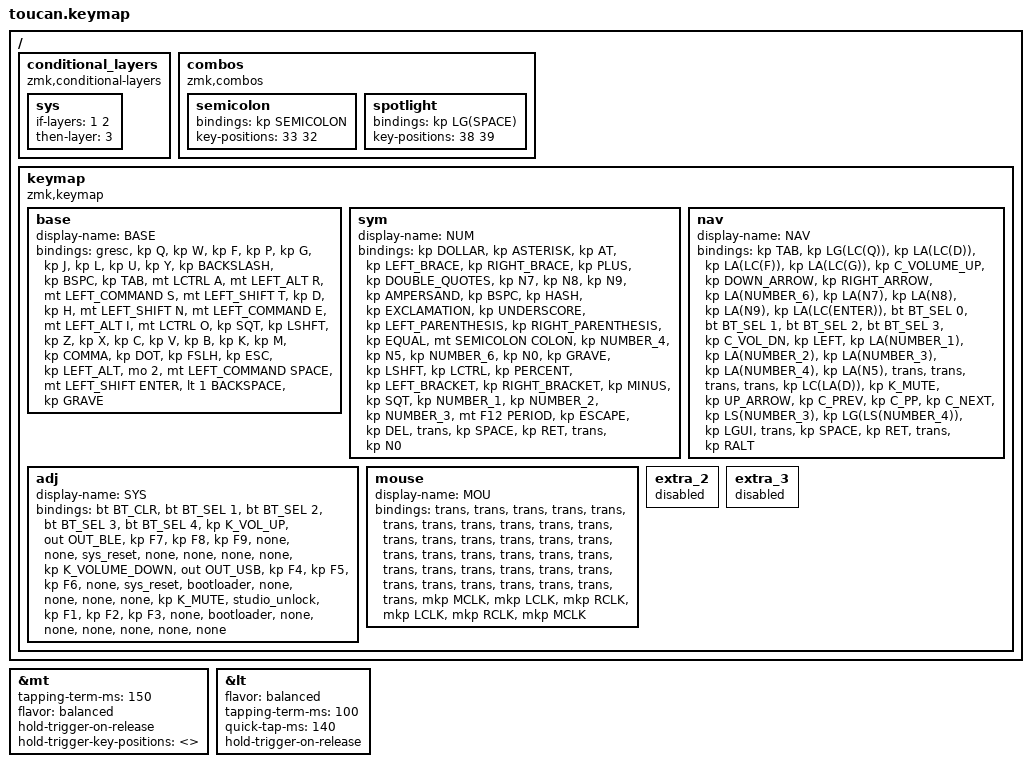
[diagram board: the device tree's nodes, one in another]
#include <behaviors.dtsi>
#include <dt-bindings/zmk/bt.h>
#include <dt-bindings/zmk/keys.h>
#include <dt-bindings/zmk/outputs.h>
#include <dt-bindings/zmk/pointing.h>

#define BASE 0
#define NAV  1
#define SYM  2
#define ADJ  3

&mt {
    tapping-term-ms = <150>;
    flavor = "balanced";
    hold-trigger-on-release;
    hold-trigger-key-positions = <>;
};

&lt {
    flavor = "balanced";
    tapping-term-ms = <100>;
    quick-tap-ms = <140>;
    hold-trigger-on-release;
};

/ {
    conditional_layers {
        compatible = "zmk,conditional-layers";

        sys {
            if-layers = <1 2>;
            then-layer = <3>;
        };
    };

    combos {
        compatible = "zmk,combos";

        semicolon {
            bindings = <&kp SEMICOLON>;
            key-positions = <33 32>;
        };

        spotlight {
            bindings = <&kp LG(SPACE)>;
            key-positions = <38 39>;
        };
    };

    keymap {
        compatible = "zmk,keymap";

        base {
            display-name = "BASE";
            bindings = <
&gresc  &kp Q  &kp W  &kp F  &kp P  &kp G  &kp J  &kp L  &kp U  &kp Y  &kp BACKSLASH  &kp BSPC  &kp TAB  &mt LCTRL A  &mt LEFT_ALT R  &mt LEFT_COMMAND S  &mt LEFT_SHIFT T  &kp D  &kp H  &mt LEFT_SHIFT N  &mt LEFT_COMMAND E  &mt LEFT_ALT I  &mt LCTRL O  &kp SQT  &kp LSHFT  &kp Z  &kp X  &kp C  &kp V  &kp B  &kp K  &kp M  &kp COMMA  &kp DOT  &kp FSLH  &kp ESC  &kp LEFT_ALT  &mo 2  &mt LEFT_COMMAND SPACE  &mt LEFT_SHIFT ENTER  &lt 1 BACKSPACE  &kp GRAVE
            >;
        };

        sym {
            display-name = "NUM";
            bindings = <
&kp DOLLAR  &kp ASTERISK  &kp AT  &kp LEFT_BRACE  &kp RIGHT_BRACE  &kp PLUS  &kp DOUBLE_QUOTES  &kp N7  &kp N8  &kp N9  &kp AMPERSAND  &kp BSPC  &kp HASH  &kp EXCLAMATION  &kp UNDERSCORE  &kp LEFT_PARENTHESIS  &kp RIGHT_PARENTHESIS  &kp EQUAL  &mt SEMICOLON COLON  &kp NUMBER_4  &kp N5  &kp NUMBER_6  &kp N0  &kp GRAVE  &kp LSHFT  &kp LCTRL  &kp PERCENT  &kp LEFT_BRACKET  &kp RIGHT_BRACKET  &kp MINUS  &kp SQT  &kp NUMBER_1  &kp NUMBER_2  &kp NUMBER_3  &mt F12 PERIOD  &kp ESCAPE  &kp DEL  &trans  &kp SPACE  &kp RET  &trans  &kp N0
            >;
        };

        nav {
            display-name = "NAV";
            bindings = <
&kp TAB  &kp LG(LC(Q))  &kp LA(LC(D))  &kp LA(LC(F))  &kp LA(LC(G))  &kp C_VOLUME_UP  &kp DOWN_ARROW  &kp RIGHT_ARROW  &kp LA(NUMBER_6)  &kp LA(N7)  &kp LA(N8)  &kp LA(N9)  &kp LA(LC(ENTER))  &bt BT_SEL 0  &bt BT_SEL 1  &bt BT_SEL 2  &bt BT_SEL 3  &kp C_VOL_DN  &kp LEFT  &kp LA(NUMBER_1)  &kp LA(NUMBER_2)  &kp LA(NUMBER_3)  &kp LA(NUMBER_4)  &kp LA(N5)  &trans  &trans  &trans  &trans  &kp LC(LA(D))  &kp K_MUTE  &kp UP_ARROW  &kp C_PREV  &kp C_PP  &kp C_NEXT  &kp LS(NUMBER_3)  &kp LG(LS(NUMBER_4))  &kp LGUI  &trans  &kp SPACE  &kp RET  &trans  &kp RALT
            >;
        };

        adj {
            display-name = "SYS";
            bindings = <
&bt BT_CLR  &bt BT_SEL 1  &bt BT_SEL 2  &bt BT_SEL 3  &bt BT_SEL 4  &kp K_VOL_UP  &out OUT_BLE  &kp F7  &kp F8  &kp F9  &none  &none  &sys_reset  &none  &none  &none  &none  &kp K_VOLUME_DOWN  &out OUT_USB  &kp F4  &kp F5  &kp F6  &none  &sys_reset  &bootloader  &none  &none  &none  &none  &kp K_MUTE  &studio_unlock  &kp F1  &kp F2  &kp F3  &none  &bootloader  &none  &none  &none  &none  &none  &none
            >;
        };

        mouse {
            display-name = "MOU";
            bindings = <
&trans  &trans  &trans  &trans  &trans  &trans  &trans  &trans  &trans  &trans  &trans  &trans  &trans  &trans  &trans  &trans  &trans  &trans  &trans  &trans  &trans  &trans  &trans  &trans  &trans  &trans  &trans  &trans  &trans  &trans  &trans  &trans  &trans  &trans  &trans  &trans  &mkp MCLK  &mkp LCLK  &mkp RCLK  &mkp LCLK  &mkp RCLK  &mkp MCLK
            >;
        };

        extra_2 { status = "reserved"; };

        extra_3 { status = "reserved"; };
    };
};
